# R7FA6M2AF register map
Vendor: Renesas; Series: RA6; File version: 1.2
CPU: CM4 r0p1, little endian, MPU, FPU, VTOR, 4 interrupt priority bits
Registers are 8-bit, read-write, reset 0x0 unless marked. A register's access mark holds for its fields unless they carry their own. Offsets are from the block's base; [hi:lo] are bit positions.

## SSIE0 — Serial Sound Interface Enhanced (SSIE)
Base 0x4004E000
Same registers: SSIE1 0x4004E100
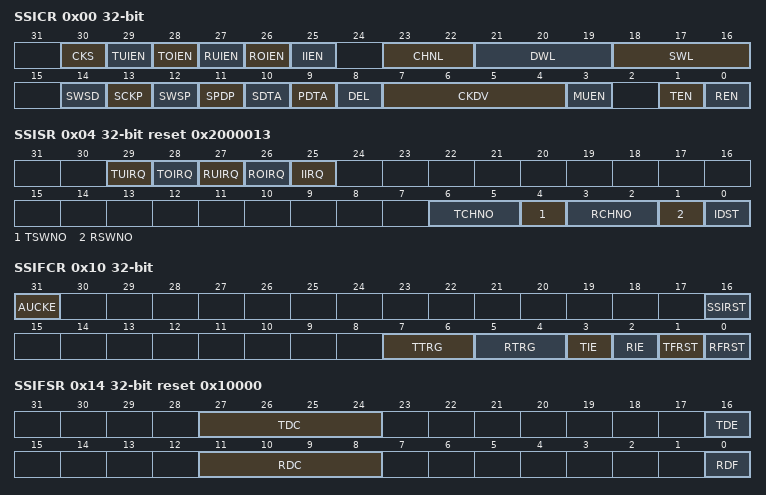
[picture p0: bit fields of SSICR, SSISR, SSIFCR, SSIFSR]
0x00 SSICR 32-bit — Control Register
  [30] CKS — Oversampling Clock Select
  [29] TUIEN — Transmit Underflow Interrupt Enable
  [28] TOIEN — Transmit Overflow Interrupt Enable
  [27] RUIEN — Receive Underflow Interrupt Enable
  [26] ROIEN — Receive Overflow Interrupt Enable
  [25] IIEN — Idle Mode Interrupt Enable
  [23:22] CHNL — Channels
  [21:19] DWL — Data Word Length
  [18:16] SWL — System Word LengthSet the system word length to the bit clock frequency/2 fs.
  [14] SWSD — Serial WS Direction NOTE: Only the following settings are allowed: (SCKD, SWSD) = (0, 0) and (1, 1). Other settings are prohibited.
  [13] SCKP — Serial Bit Clock Polarity
  [12] SWSP — Serial WS Polarity
  [11] SPDP — Serial Padding Polarity
  [10] SDTA — Serial Data Alignment
  [9] PDTA — Parallel Data Alignment
  [8] DEL — Serial Data Delay
  [7:4] CKDV — Serial Oversampling Clock Division Ratio
  [3] MUEN — Mute EnableNOTE: When this module is muted, the value of outputting serial data is rewritten to 0 but data transmission is not stopped. Write dummy data to the SSIFTDR not to generate a transmit underflow because the number of data in the transmit FIFO is decreasing.
  [1] TEN — Transmit Enable
  [0] REN — Receive Enable
0x04 SSISR 32-bit reset 0x2000013 — Status Register
  [29] TUIRQ write-0-clears read-modifies — Transmit Underflow Error Interrupt Status Flag NOTE: Writable only to clear the flag. Confirm the value is 1 and then write 0.
  [28] TOIRQ write-0-clears read-modifies — Transmit Overflow Error Interrupt Status Flag NOTE: Writable only to clear the flag. Confirm the value is 1 and then write 0.
  [27] RUIRQ write-0-clears read-modifies — Receive Underflow Error Interrupt Status Flag NOTE: Writable only to clear the flag. Confirm the value is 1 and then write 0.
  [26] ROIRQ write-0-clears read-modifies — Receive Overflow Error Interrupt Status Flag NOTE: Writable only to clear the flag. Confirm the value is 1 and then write 0.
  [25] IIRQ ro — Idle Mode Interrupt Status Flag
  [6:5] TCHNO ro — Transmit Channel Number
  [4] TSWNO ro — Transmit Serial Word Number
  [3:2] RCHNO ro — Receive Channel Number.These bits are read as 00b.
  [1] RSWNO ro — Receive Serial Word Number
  [0] IDST ro — Idle Mode Status Flag
0x10 SSIFCR 32-bit — FIFO Control Register
  [31] AUCKE — Oversampling Clock Enable
  [16] SSIRST — SSI soft ware reset
  [7:6] TTRG — Transmit Data Trigger Number NOTE: The values in parenthesis are the number of empty stages in SSIFTDR at which the TDE flag is set.
  [5:4] RTRG — Receive Data Trigger Number
  [3] TIE — Transmit Interrupt Enable NOTE: TXI can be cleared by clearing either the TDE flag (see the description of the TDE bit for details) or TIE bit.
  [2] RIE — Receive Interrupt Enable NOTE: RXI can be cleared by clearing either the RDF flag (see the description of the RDF bit for details) or RIE bit.
  [1] TFRST — Transmit FIFO Data Register Reset
  [0] RFRST — Receive FIFO Data Register Reset
0x14 SSIFSR 32-bit reset 0x10000 — FIFO Status Register
  [27:24] TDC ro — Transmit Data Indicate Flag(Indicates the number of data units stored in SSIFTDR)
  [16] TDE write-0-clears read-modifies — Transmit Data Empty Flag NOTE: Since the SSIFTDR register is a 32-byte FIFO register, the maximum number of bytes that can be written to it while the TDE flag is 1 is 8 - TDC[3:0]. If writing data to the SSIFTDR register is continued after all the data is written, writing will be invalid and an overflow occurs.
  [11:8] RDC ro — Receive Data Indicate Flag(Indicates the number of data units stored in SSIFRDR)
  [0] RDF write-0-clears read-modifies — Receive Data Full Flag NOTE: Since the SSIFRDR register is a 32-byte FIFO register, the maximum number of data bytes that can be read from it while the RDF flag is 1 is indicated in the RDC[3:0] flags. If reading data from the SSIFRDR register is continued after all the data is read, undefined values will be read.
0x18 SSIFTDR 32-bit wo reset not defined — Transmit FIFO Data Register
  [31:0] SSIFTDR — SSIFTDR is a write,only FIFO register consisting of eight stages of 32-bit registers for storing data to be serially transmitted. NOTE: that when the SSIFTDR register is full of data (32 bytes), the next data cannot be written to it. If writing is attempted, it will be ignored and an overflow occurs.
0x1C SSIFRDR 32-bit ro reset not defined — Receive FIFO Data Register
  [31:0] SSIFRDR — SSIFRDR is a read,only FIFO register consisting of eight stages of 32-bit registers for storing serially received data.
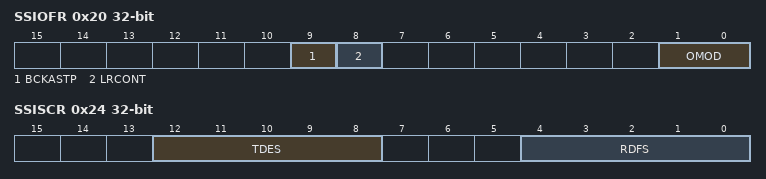
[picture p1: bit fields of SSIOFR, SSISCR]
0x20 SSIOFR 32-bit — Audio Format Register
  [9] BCKASTP — Whether to Enable Stopping BCK Output When SSIE is in Idle Status
  [8] LRCONT — Whether to Enable LRCK/FS Continuation
  [1:0] OMOD — Audio Format Select
0x24 SSISCR 32-bit — Status Control Register
  [12:8] TDES — TDE Setting Condition Select
  [4:0] RDFS — RDF Setting Condition Select
